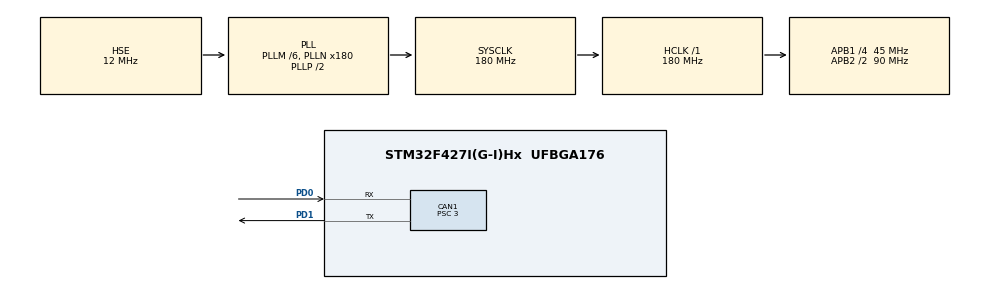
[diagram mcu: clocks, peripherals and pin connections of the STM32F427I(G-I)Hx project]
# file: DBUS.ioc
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CAN1.ABOM=ENABLE
CAN1.BS1=CAN_BS1_11TQ
CAN1.BS2=CAN_BS2_3TQ
CAN1.CalculateBaudRate=1000000
CAN1.CalculateTimeBit=1000
CAN1.CalculateTimeQuantum=66.66666666666666
CAN1.Prescaler=3
Mcu.Family=STM32F4
Mcu.Name=STM32F427I(G-I)Hx
Mcu.Package=UFBGA176
NVIC.CAN1_RX0_IRQn=true\:0\:0\:false\:false\:true\:true\:true\:true
NVIC.CAN1_RX1_IRQn=true\:0\:0\:false\:false\:true\:true\:true\:true
NVIC.PriorityGroup=NVIC_PRIORITYGROUP_4
PA13.Mode=Serial_Wire
PA13.Signal=SYS_JTMS-SWDIO
PA14.Mode=Serial_Wire
PA14.Signal=SYS_JTCK-SWCLK
PB7.Signal=USART1_RX
PC14/OSC32_IN.Mode=LSE-External-Oscillator
PC14/OSC32_IN.Signal=RCC_OSC32_IN
PC15/OSC32_OUT.Mode=LSE-External-Oscillator
PC15/OSC32_OUT.Signal=RCC_OSC32_OUT
PD0.Mode=CAN_Activate
PD0.Signal=CAN1_RX
PD1.Mode=CAN_Activate
PD1.Signal=CAN1_TX
PH0/OSC_IN.Mode=HSE-External-Oscillator
PH0/OSC_IN.Signal=RCC_OSC_IN
PH1/OSC_OUT.Mode=HSE-External-Oscillator
PH1/OSC_OUT.Signal=RCC_OSC_OUT
ProjectManager.HeapSize=0x200
ProjectManager.StackSize=0x400
ProjectManager.TargetToolchain=MDK-ARM V5.32
RCC.48MHZClocksFreq_Value=90000000
RCC.AHBFreq_Value=180000000
RCC.APB1CLKDivider=RCC_HCLK_DIV4
RCC.APB1Freq_Value=45000000
RCC.APB1TimFreq_Value=90000000
RCC.APB2CLKDivider=RCC_HCLK_DIV2
RCC.APB2Freq_Value=90000000
RCC.APB2TimFreq_Value=180000000
RCC.CortexFreq_Value=180000000
RCC.HCLKFreq_Value=180000000
RCC.HSE_VALUE=12000000
RCC.HSI_VALUE=16000000
RCC.PLLM=6
RCC.PLLN=180
RCC.PLLSourceVirtual=RCC_PLLSOURCE_HSE
RCC.SYSCLKFreq_VALUE=180000000
RCC.SYSCLKSource=RCC_SYSCLKSOURCE_PLLCLK
RCC.VCOOutputFreq_Value=360000000
board=custom

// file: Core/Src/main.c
/* USER CODE BEGIN Header */
/**
  ******************************************************************************
  * @file           : main.c
  * @brief          : Main program body
  ******************************************************************************
  * @attention
  *
  * Copyright (c) 2024 STMicroelectronics.
  * All rights reserved.
  *
  * This software is licensed under terms that can be found in the LICENSE file
  * in the root directory of this software component.
  * If no LICENSE file comes with this software, it is provided AS-IS.
  *
  ******************************************************************************
  */
/* USER CODE END Header */
#include "main.h"
#include "can.h"
#include "gpio.h"

void SystemClock_Config(void);

/* USER CODE BEGIN 0 */
CAN_RxHeaderTypeDef RxHeader;
CAN_TxHeaderTypeDef TxHeader;
uint8_t RxData[8];
uint8_t TxData[8] = {0x00, 0xF7, 0x00, 0x77, 0x00, 0x00, 0x00, 0x00};
uint32_t TxMailbox = CAN_TX_MAILBOX0;

float motor_angle;
float motor_speed;
float motor_current;
float motor_temperature;
/* USER CODE END 0 */

int main(void)
{

  /* MCU Configuration--------------------------------------------------------*/

  /* Reset of all peripherals, Initializes the Flash interface and the Systick. */
  HAL_Init();

  /* Configure the system clock */
  SystemClock_Config();

  /* Initialize all configured peripherals */
  MX_GPIO_Init();
  MX_CAN1_Init();
  /* USER CODE BEGIN 2 */
  CAN_FilterTypeDef FilterConfig = {0};
  FilterConfig.FilterBank = 0;
  FilterConfig.FilterMode = CAN_FILTERMODE_IDMASK;
  FilterConfig.FilterScale = CAN_FILTERSCALE_32BIT;
  FilterConfig.FilterIdHigh = 0x0000;
  FilterConfig.FilterIdLow = 0x0000;
  FilterConfig.FilterMaskIdHigh = 0x0000;
  FilterConfig.FilterMaskIdLow = 0x0000;
  FilterConfig.FilterFIFOAssignment = CAN_FILTER_FIFO0;
  FilterConfig.FilterActivation = CAN_FILTER_ENABLE;

  HAL_CAN_ConfigFilter(&hcan1, &FilterConfig);
  HAL_CAN_Start(&hcan1);
  HAL_CAN_ActivateNotification(&hcan1, CAN_IT_RX_FIFO0_MSG_PENDING);

  TxHeader.StdId = 0x200;
  TxHeader.ExtId = 0x00;
  TxHeader.IDE = CAN_ID_STD;
  TxHeader.RTR = CAN_RTR_DATA;
  TxHeader.DLC = 8;
  TxHeader.TransmitGlobalTime = DISABLE;

  /* USER CODE END 2 */

  /* Infinite loop */
  while (1)
  {
    HAL_CAN_AddTxMessage(&hcan1, &TxHeader, TxData, &TxMailbox);
    HAL_Delay(1000);
  }
}

void SystemClock_Config(void)
{
  RCC_OscInitTypeDef RCC_OscInitStruct = {0};
  RCC_ClkInitTypeDef RCC_ClkInitStruct = {0};

  /** Configure the main internal regulator output voltage
  */
  __HAL_RCC_PWR_CLK_ENABLE();
  __HAL_PWR_VOLTAGESCALING_CONFIG(PWR_REGULATOR_VOLTAGE_SCALE1);

  /** Initializes the RCC Oscillators according to the specified parameters
  * in the RCC_OscInitTypeDef structure.
  */
  RCC_OscInitStruct.OscillatorType = RCC_OSCILLATORTYPE_HSE;
  RCC_OscInitStruct.HSEState = RCC_HSE_ON;
  RCC_OscInitStruct.PLL.PLLState = RCC_PLL_ON;
  RCC_OscInitStruct.PLL.PLLSource = RCC_PLLSOURCE_HSE;
  RCC_OscInitStruct.PLL.PLLM = 6;
  RCC_OscInitStruct.PLL.PLLN = 180;
  RCC_OscInitStruct.PLL.PLLP = RCC_PLLP_DIV2;
  RCC_OscInitStruct.PLL.PLLQ = 4;
  if (HAL_RCC_OscConfig(&RCC_OscInitStruct) != HAL_OK)
  {
    Error_Handler();
  }

  /** Activate the Over-Drive mode
  */
  if (HAL_PWREx_EnableOverDrive() != HAL_OK)
  {
    Error_Handler();
  }

  /** Initializes the CPU, AHB and APB buses clocks
  */
  RCC_ClkInitStruct.ClockType = RCC_CLOCKTYPE_HCLK|RCC_CLOCKTYPE_SYSCLK
                              |RCC_CLOCKTYPE_PCLK1|RCC_CLOCKTYPE_PCLK2;
  RCC_ClkInitStruct.SYSCLKSource = RCC_SYSCLKSOURCE_PLLCLK;
  RCC_ClkInitStruct.AHBCLKDivider = RCC_SYSCLK_DIV1;
  RCC_ClkInitStruct.APB1CLKDivider = RCC_HCLK_DIV4;
  RCC_ClkInitStruct.APB2CLKDivider = RCC_HCLK_DIV2;

  if (HAL_RCC_ClockConfig(&RCC_ClkInitStruct, FLASH_LATENCY_5) != HAL_OK)
  {
    Error_Handler();
  }
}

void Error_Handler(void)
{
  __disable_irq();
  while (1)
  {
  }
}
